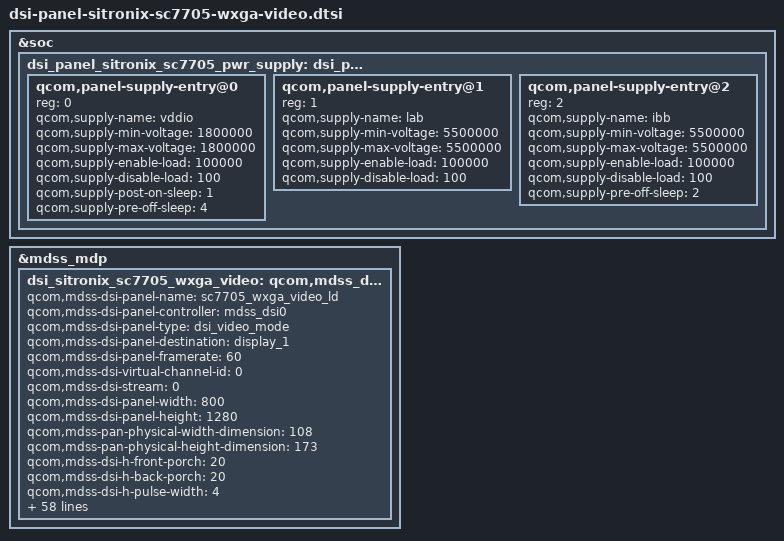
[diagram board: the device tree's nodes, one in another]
/* Copyright (c) 2013, The Linux Foundation. All rights reserved.
 *
 * This program is free software; you can redistribute it and/or modify
 * it under the terms of the GNU General Public License version 2 and
 * only version 2 as published by the Free Software Foundation.
 *
 * This program is distributed in the hope that it will be useful,
 * but WITHOUT ANY WARRANTY; without even the implied warranty of
 * MERCHANTABILITY or FITNESS FOR A PARTICULAR PURPOSE.  See the
 * GNU General Public License for more details.
 */

/*---------------------------------------------------------------------------
 * This file is autogenerated file using gcdb parser. Please do not edit it.
 * Update input XML file to add a new entry or update variable in this file
 * VERSION = "1.0"
 *---------------------------------------------------------------------------*/
&soc {
	dsi_panel_sitronix_sc7705_pwr_supply: dsi_panel_sc7705_pwr_supply {
		#address-cells = <1>;
		#size-cells = <0>;

		qcom,panel-supply-entry@0 {
			reg = <0>;
			qcom,supply-name = "vddio";
			qcom,supply-min-voltage = <1800000>;
			qcom,supply-max-voltage = <1800000>;
			qcom,supply-enable-load = <100000>;
			qcom,supply-disable-load = <100>;
			qcom,supply-post-on-sleep = <1>;
			qcom,supply-pre-off-sleep = <4>;
		};

		qcom,panel-supply-entry@1 {
			reg = <1>;
			qcom,supply-name = "lab";
			qcom,supply-min-voltage = <5500000>;
			qcom,supply-max-voltage = <5500000>;
			qcom,supply-enable-load = <100000>;
			qcom,supply-disable-load = <100>;
			//qcom,supply-post-off-sleep = <1>;
		};

		qcom,panel-supply-entry@2 {
			reg = <2>;
			qcom,supply-name = "ibb";
			qcom,supply-min-voltage = <5500000>;
			qcom,supply-max-voltage = <5500000>;
			qcom,supply-enable-load = <100000>;
			qcom,supply-disable-load = <100>;
			qcom,supply-pre-off-sleep = <2>;
			//qcom,supply-post-on-sleep = <6>;
		};
	};
};
&mdss_mdp {
	dsi_sitronix_sc7705_wxga_video: qcom,mdss_dsi_sitronix_sc7705_wxga_video{
		qcom,mdss-dsi-panel-name = "sc7705_wxga_video_ld";	//Bug601075, shenwenbin.wt, add, 20201230 mv N8_Q code to N8_R
		qcom,mdss-dsi-panel-controller = <&mdss_dsi0>;
		qcom,mdss-dsi-panel-type = "dsi_video_mode";
		qcom,mdss-dsi-panel-destination = "display_1";
		qcom,mdss-dsi-panel-framerate = <60>;
		qcom,mdss-dsi-virtual-channel-id = <0>;
		qcom,mdss-dsi-stream = <0>;
		qcom,mdss-dsi-panel-width = <800>;
		qcom,mdss-dsi-panel-height = <1280>;
		qcom,mdss-pan-physical-width-dimension = <108>;
		qcom,mdss-pan-physical-height-dimension = <173>;
		qcom,mdss-dsi-h-front-porch = <20>;	//Bug604581, shenwenbin.wt, add, 20201203, panel noise and TP fiddling report point
		qcom,mdss-dsi-h-back-porch = <20>;	//Bug604581, shenwenbin.wt, add, 20201203, panel noise and TP fiddling report point
		qcom,mdss-dsi-h-pulse-width = <4>;	//Bug604581, shenwenbin.wt, add, 20201203, panel noise and TP fiddling report point
		qcom,mdss-dsi-h-sync-skew = <0>;
		qcom,mdss-dsi-v-back-porch = <9>;
		qcom,mdss-dsi-v-front-porch = <12>;
		qcom,mdss-dsi-v-pulse-width = <3>;
		qcom,mdss-dsi-h-left-border = <0>;
		qcom,mdss-dsi-h-right-border = <0>;
		qcom,mdss-dsi-v-top-border = <0>;
		qcom,mdss-dsi-v-bottom-border = <0>;
		qcom,mdss-dsi-bpp = <24>;
		qcom,mdss-dsi-color-order = "rgb_swap_rgb";
		qcom,mdss-dsi-underflow-color = <0xff>;
		qcom,mdss-dsi-border-color = <0>;
		//+Bug601075, shenwenbin.wt, add, 20201230 mv N8_Q code to N8_R
		qcom,mdss-dsi-on-command = [
		        39 01 00 00 00 00 04 B9 F1 12 84
		        39 01 00 00 00 00 1c BA 33 81 05 F9 0E 0E 02 00 00 00 00 00 00 00 44 25 00 90 0A 00 00 01 4F 01 FF FA 37
		        39 01 00 00 00 00 03 B2 40 08
		        39 01 00 00 00 00 02 CC 0B
		        39 01 00 00 00 00 03 B8 38 03
		        39 01 00 00 00 00 09 B3 00 00 00 00 28 28 28 28
		        39 01 00 00 00 00 0a C0 73 73 50 50 80 00 08 C0 00
		        39 01 00 00 00 00 04 BF 00 11 82
		        39 01 00 00 00 00 02 BC 46
		        39 01 00 00 00 00 02 B4 80
		        39 01 00 00 00 00 0c E3 1C 1C 0B 0B 00 00 00 00 00 C0 20
		        39 01 00 00 00 00 0b B1 23 55 23 2F 2F 88 77 01 DB CC
		        39 01 00 00 00 00 03 B5 10 10
		        39 01 00 00 00 00 03 B6 72 7A
				39 01 00 00 00 00 06 E1 33 43 0b 00 70
		        39 01 00 00 00 00 40 E9 08 00 05 00 00 80 81 12 31 23 47 09 80 81 47 08 00 81 00 00 00 00 00 81 00 00 00 00 F8 AB 46 02 08 88 88 82 88 88 88 F8 AB 57 13 18 88 88 83 88 88 88 00 00 00 01 00 00 00 00 00 00 00 00 00
		        39 01 00 00 00 00 40 EA 96 12 01 01 02 3C 00 00 00 00 00 00 8F AB 31 75 38 88 88 81 88 88 88 8F AB 20 64 28 88 88 80 88 88 88 23 00 00 00 01 78 00 00 00 00 00 00 00 00 00 00 00 00 00 00 40 80 81 00 00 00 00 01 11
		        39 01 00 00 00 00 23 E0 00 0B 11 36 3F 3F 46 3E 06 0C 0D 12 14 12 14 0F 0F 06 0B 11 36 3F 3F 46 3E 06 0C 0D 12 14 12 14 0F 0F
				39 01 00 00 00 00 0b C7 00 00 02 00 00 00 00 00 00 04
				05 01 00 00 78 00 02 11 00
				05 01 00 00 14 00 02 29 00
		];
		//-Bug601075, shenwenbin.wt, add, 20201230 mv N8_Q code to N8_R
		qcom,mdss-dsi-off-command = [
			05 01 00 00 14 00 02 28 00
			05 01 00 00 78 00 02 10 00];
		qcom,mdss-dsi-on-command-state = "dsi_lp_mode";
		qcom,mdss-dsi-off-command-state = "dsi_lp_mode";
		qcom,mdss-dsi-h-sync-pulse = <1>;
		qcom,mdss-dsi-traffic-mode = "burst_mode";
		qcom,mdss-dsi-lane-map = "lane_map_0123";
		qcom,mdss-dsi-bllp-eof-power-mode;
		qcom,mdss-dsi-bllp-power-mode;
		qcom,mdss-dsi-lane-0-state;
		qcom,mdss-dsi-lane-1-state;
		qcom,mdss-dsi-lane-2-state;
		qcom,mdss-dsi-lane-3-state;
		qcom,mdss-dsi-panel-timings-phy-12nm = [08 05 09 02 00 04 02 07];	//Bug604581, shenwenbin.wt, add, 20201203, panel noise and TP fiddling report point
		//qcom,mdss-dsi-t-clk-post = <0x04>;
		//qcom,mdss-dsi-t-clk-pre = <0x26>;
		qcom,mdss-dsi-dma-trigger = "trigger_sw";
		qcom,mdss-dsi-mdp-trigger = "none";
		qcom,mdss-dsi-bl-min-level = <1>;
		qcom,mdss-dsi-bl-max-level = <255>;
		qcom,mdss-dsi-bl-pmic-control-type = "bl_ctrl_pwm";
		qcom,mdss-dsi-bl-pmic-pwm-frequency = <50>;
		qcom,mdss-dsi-bl-pmic-bank-select = <0>;
		qcom,mdss-dsi-pwm-gpio = <&pm8953_gpios 8 0>;
		ss,blmap-size = <256>;
		ss,blmap = < 0 2 2 2 2 2 2 2 2 2
					2 2 3 3 4 5 6 7 8 9
					10 11 12 13 14 15 16 17 18 19
					20 21 22 23 24 25 26 27 28 29
					30 31 32 33 34 35 36 37 38 39
					40 41 42 43 44 45 46 47 48 49
					50 51 52 53 54 55 56 57 58 59
					60 61 62 63 64 65 66 67 68 69
					70 71 72 73 74 75 76 77 78 79
					80 81 82 83 84 85 86 87 88 89
					90 91 92 93 94 95 96 97 98 99
					100 101 102 103 104 105 106 107 108 109
					110 111 112 113 114 115 116 117 118 119
					120 121 122 123 124 125 126 127 128 129
					130 131 132 133 134 135 136 137 138 139
					140 141 142 143 144 145 146 147 148 149
					150 151 152 153 154 155 156 157 158 159
					160 161 162 163 164 165 166 167 168 169
					170 171 172 173 174 175 176 177 178 179
					180 181 182 183 184 185 186 187 188 189
					190 191 192 193 194 195 196 197 198 199
					200 201 202 203 204 205 206 207 208 209
					210 211 212 213 214 215 216 217 218 219
					220 221 222 223 224 225 226 227 228 229
					230 231 232 233 234 236 238 240 242 244
					246 248 250 252 254 255>;

		qcom,mdss-dsi-lp11-init;
		qcom,mdss-dsi-init-delay-us = <1000>;
		qcom,mdss-dsi-reset-sequence = <1 10>, <0 10>, <1 50>;
		qcom,esd-check-enabled;
		//+Bug601075, shenwenbin.wt, add, 20201230 mv N8_Q code to N8_R
		qcom,mdss-dsi-panel-status-command = [06 01 00 01 05 00 01 09
						      06 01 00 01 05 00 01 BA
						      06 01 00 01 05 00 01 AF];
		qcom,mdss-dsi-panel-status-command-state = "dsi_lp_mode";
		qcom,mdss-dsi-panel-status-check-mode = "reg_read";
		qcom,mdss-dsi-panel-status-read-length = <3 7 1>;
		qcom,mdss-dsi-panel-status-valid-params = <3 7 1>;
		qcom,mdss-dsi-panel-status-value =
			<0x80 0x73 0x04 0x33 0x81 0x05 0xF9 0x0E 0x0E 0x02 0xFD>;
		qcom,mdss-dsi-panel-max-error-count = <3>;
		//-Bug601075, shenwenbin.wt, add, 20201230 mv N8_Q code to N8_R
		qcom,panel-supply-entries = <&dsi_panel_sitronix_sc7705_pwr_supply>;
	};
};
